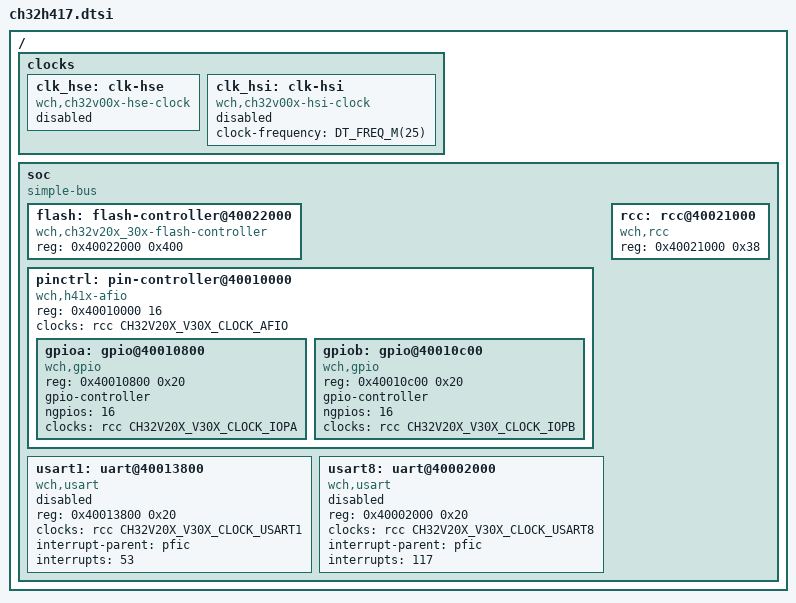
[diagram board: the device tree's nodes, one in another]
/*
 * Copyright (c) 2026 Liu Changjie
 *
 * SPDX-License-Identifier: Apache-2.0
 */

#include <freq.h>
#include <mem.h>

#include <zephyr/dt-bindings/gpio/gpio.h>
#include <zephyr/dt-bindings/clock/ch32v20x_30x-clocks.h>

/ {
	#address-cells = <1>;
	#size-cells = <1>;

	clocks {
		clk_hse: clk-hse {
			#clock-cells = <0>;
			compatible = "wch,ch32v00x-hse-clock";
			/* HSE crystal frequency is board-specific; set it in the board DTS. */
			status = "disabled";
		};

		clk_hsi: clk-hsi {
			#clock-cells = <0>;
			compatible = "wch,ch32v00x-hsi-clock";
			clock-frequency = <DT_FREQ_M(25)>;
			status = "disabled";
		};
	};

	soc {
		#address-cells = <1>;
		#size-cells = <1>;
		compatible = "simple-bus";
		ranges;

		flash: flash-controller@40022000 {
			compatible = "wch,ch32v20x_30x-flash-controller";
			reg = <0x40022000 0x400>;
			ranges;

			#address-cells = <1>;
			#size-cells = <1>;
		};

		pinctrl: pin-controller@40010000 {
			compatible = "wch,h41x-afio";
			reg = <0x40010000 16>;
			#address-cells = <1>;
			#size-cells = <1>;
			clocks = <&rcc CH32V20X_V30X_CLOCK_AFIO>;

			gpioa: gpio@40010800 {
				compatible = "wch,gpio";
				reg = <0x40010800 0x20>;
				gpio-controller;
				#gpio-cells = <2>;
				ngpios = <16>;
				clocks = <&rcc CH32V20X_V30X_CLOCK_IOPA>;
			};

			gpiob: gpio@40010c00 {
				compatible = "wch,gpio";
				reg = <0x40010c00 0x20>;
				gpio-controller;
				#gpio-cells = <2>;
				ngpios = <16>;
				clocks = <&rcc CH32V20X_V30X_CLOCK_IOPB>;
			};
		};

		usart1: uart@40013800 {
			compatible = "wch,usart";
			reg = <0x40013800 0x20>;
			clocks = <&rcc CH32V20X_V30X_CLOCK_USART1>;
			interrupt-parent = <&pfic>;
			interrupts = <53>;
			status = "disabled";
		};

		usart8: uart@40002000 {
			compatible = "wch,usart";
			reg = <0x40002000 0x20>;
			clocks = <&rcc CH32V20X_V30X_CLOCK_USART8>;
			interrupt-parent = <&pfic>;
			interrupts = <117>;
			status = "disabled";
		};

		rcc: rcc@40021000 {
			compatible = "wch,rcc";
			reg = <0x40021000 0x38>;
			#clock-cells = <1>;
			status = "okay";
		};
	};
};
